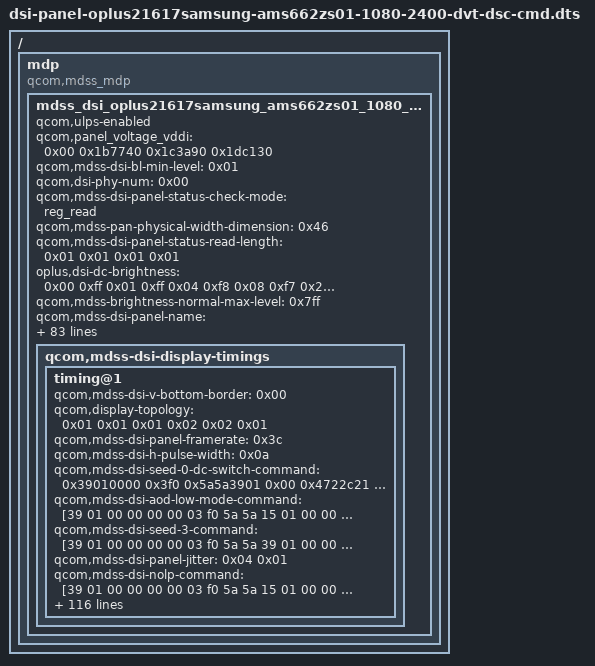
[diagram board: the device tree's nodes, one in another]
/dts-v1/;

/ {
	mdp {
		compatible = "qcom,mdss_mdp";
		mdss_dsi_oplus21617samsung_ams662zs01_1080_2400_cmd_dvt: qcom,mdss_dsi_oplus21617samsung_ams662zs01_1080_2400_cmd_dvt {
			qcom,ulps-enabled;
			qcom,panel_voltage_vddi = <0x00 0x1b7740 0x1c3a90 0x1dc130>;
			qcom,mdss-dsi-bl-min-level = <0x01>;
			qcom,dsi-phy-num = <0x00>;
			qcom,mdss-dsi-panel-status-check-mode = "reg_read";
			qcom,mdss-pan-physical-width-dimension = <0x46>;
			qcom,mdss-dsi-panel-status-read-length = <0x01 0x01 0x01 0x01>;
			oplus,dsi-dc-brightness = <0x00 0xff 0x01 0xff 0x04 0xf8 0x08 0xf7 0x23 0xf5 0x69 0xf3 0xc3 0xf0 0xeb 0xee 0x131 0xe9 0x190 0xe1 0x1f4 0xd7 0x244 0xcd 0x24f 0xc3 0x294 0xaf 0x2d0 0x9b 0x30c 0x87 0x339 0x73 0x361 0x5f 0x384 0x4c 0x3c3 0x37 0x3e8 0x26 0x41a 0x12 0x44c 0x00>;
			qcom,mdss-brightness-normal-max-level = <0x7ff>;
			qcom,mdss-dsi-panel-name = "samsung ams662zs01 dvt dsc cmd mode panel";
			oplus,mdss-dsi-osc-clk-mode1-rate = <0x2c81c>;
			qcom,mdss-pan-physical-height-dimension = <0x99>;
			oplus,dc-apollo-backlight-sync-level = <0x44c>;
			qcom,mdss-dsi-te-using-te-pin;
			oplus,dc_apollo_sync_enable;
			qcom,esd-check-enabled;
			qcom,mdss-dsi-dc-backlight-level = <0x44c>;
			qcom,mdss-dsi-te-dcs-command = <0x01>;
			qcom,mdss-dsi-color-order = "rgb_swap_rgb";
			qcom,dsi-select-clocks = "mux_byte_clk0\0mux_pixel_clk0\0src_byte_clk0\0src_pixel_clk0\0shadow_byte_clk0\0shadow_pixel_clk0";
			qcom,mdss-dsi-panel-status-value = <0x9f 0x00 0x01 0x80>;
			qcom,mdss-dsi-underflow-color = <0xff>;
			qcom,platform-panel-vddr-aod-en-gpio = <0x93 0xa3 0x00>;
			qcom,mdss-dsi-lane-2-state;
			qcom,mdss-dsi-te-check-enable;
			qcom,mdss-dsi-bllp-eof-power-mode;
			oplus,mdss-dsi-osc-clk-mode0-rate = <0x2c04c>;
			oplus,dc-apollo-backlight-sync-level-pcc-min = <0x5460>;
			oplus,esd-err-trigger-polarity = <0x01>;
			oplus,apollo-sync-brightness-level = <0x2c7>;
			qcom,mdss-dsi-mdp-trigger = "none";
			qcom,dsi-ctrl-num = <0x00>;
			qcom,mdss-dsi-bl-max-level = <0xfff>;
			qcom,mdss-dsi-panel-blackness-level = <0x7d0>;
			oplus,dc-apollo-backlight-sync-level-pcc-max = <0x7ff8>;
			qcom,platform-reset-gpio = <0x93 0x18 0x00>;
			qcom,mdss-dsi-panel-peak-brightness = <0x5265c0>;
			qcom,mdss-dsi-lane-3-state;
			qcom,panel_voltage_vddr = <0x01 0x1b7740 0x1c3a90 0x1dc130>;
			qcom,mdss-dsi-panel-hdr-color-primaries = <0x3d13 0x4042 0x84d0 0x3e80 0x33c2 0x86c4 0x1d4c 0xbb8>;
			qcom,mdss-dsi-virtual-channel-id = <0x00>;
			oplus,apollo_backlight_enable;
			qcom,dsi-dyn-clk-enable;
			qcom,mdss-dsi-reset-sequence = <0x00 0x00 0x00 0x01 0x01 0x06>;
			qcom,dynamic-mode-switch-type = "dynamic-resolution-switch-immediate";
			oplus,esd-err-flag-gpio = <0x93 0x54 0x00>;
			qcom,mdss-dsi-panel-type = "dsi_cmd_mode";
			qcom,dynamic-mode-switch-enabled;
			qcom,dsi-dyn-clk-list = <0x2faf0800 0x3178cb80>;
			qcom,mdss-dsi-lane-0-state;
			qcom,panel_voltage_vddr_name = "vddio";
			qcom,mdss-dsi-dma-trigger = "trigger_sw";
			qcom,mdss-dsi-panel-hdr-enabled;
			qcom,mdss-dsi-panel-status-command-state = "dsi_hs_mode";
			qcom,mdss-dsi-te-pin-select = <0x01>;
			qcom,mdss-dsi-bl-normal-max-level = <0x7ff>;
			oplus,mdss-dsi-manufacture = "samsung1024";
			phandle = <0x5c5>;
			qcom,mdss-dsi-bllp-power-mode;
			qcom,panel-supply-entries = <0x61e>;
			qcom,mdss-dsi-stream = <0x00>;
			oplus,dsi-fod-brightness = <0x00 0xff 0x04 0xee 0x100 0xe5 0x10a 0xe4 0x154 0xdc 0x1ae 0xd2 0x1fa 0xca 0x244 0xc2 0x2c6 0xb8 0x2ee 0xb0 0x316 0xab 0x354 0xa5 0x37e 0xa0 0x3d6 0x98 0x41c 0x92 0x460 0x8b 0x49a 0x85 0x4c8 0x80 0x50c 0x79 0x540 0x74 0x570 0x6f 0x596 0x6a 0x5dc 0x63 0x612 0x5e 0x636 0x59 0x670 0x53 0x68a 0x50 0x6c4 0x4a 0x6f2 0x45 0x724 0x40 0x740 0x3d 0x758 0x3a 0x766 0x38 0x7a4 0x32 0x7d6 0x2c 0x7ff 0x28>;
			qcom,mdss-dsi-lp11-init;
			qcom,mdss-dsi-wr-mem-continue = <0x3c>;
			qcom,mdss-dsi-bl-pmic-control-type = "bl_ctrl_dcs";
			qcom,mdss-dsi-lane-map = "lane_map_0123";
			qcom,mdss-dsi-traffic-mode = "non_burst_sync_event";
			qcom,mdss-dsi-border-color = <0x00>;
			qcom,panel_voltage_vddi_name = "vddio";
			qcom,mdss-dsi-panel-controller = <0x519>;
			qcom,mdss-brightness-default-level = <0x190>;
			oplus,mdss-dsi-vendor-name = "AMS662ZS01";
			qcom,mdss-dsi-panel-status-command = <0x6010001 0x500020a 0x60100 0x1050002 0x5000601 0x10500 0x2030006 0x1000105 0x20e00>;
			qcom,mdss-dsi-lane-1-state;
			qcom,mdss-dsi-wr-mem-start = <0x2c>;
			qcom,platform-te-gpio = <0x93 0x52 0x00>;
			oplus,osc-support;
			qcom,mdss-dsi-bpp = <0x18>;
			qcom,mdss-brightness-max-level = <0xfff>;
			qcom,mdss-dsi-display-timings {
                                timing@1 {
					qcom,mdss-dsi-v-bottom-border = <0x00>;
					qcom,display-topology = <0x01 0x01 0x01 0x02 0x02 0x01>;
					qcom,mdss-dsi-panel-framerate = <0x3c>;
					qcom,mdss-dsi-h-pulse-width = <0x0a>;
					qcom,mdss-dsi-seed-0-dc-switch-command = <0x39010000 0x3f0 0x5a5a3901 0x00 0x4722c21 0x390100 0x02 0xf8003901 0x00 0x3f05a5a 0x39010000 0x25d 0x46390100 0x02 0x62003901 0x00 0x3b01662 0x39010000 0x1662 0xff000000 0xff000000 0xff00ffff 0xff00ffff 0xff00ffff 0xff390100 0x03 0xf0a5a539 0x1000014 0x4722c 0x1003901 0x00 0x3f0a5a5>;
					qcom,mdss-dsi-aod-low-mode-command = [39 01 00 00 00 00 03 f0 5a 5a 15 01 00 00 00 00 02 91 01 15 01 00 00 00 00 02 53 25 15 01 00 00 00 00 02 bb 1d 39 01 00 00 00 00 03 f0 a5 a5];
					qcom,mdss-dsi-seed-3-command = [39 01 00 00 00 00 03 f0 5a 5a 39 01 00 00 00 00 03 b0 03 8f 39 01 00 00 00 00 02 8f 25 39 01 00 00 00 00 03 b0 28 f2 39 01 00 00 00 00 02 f2 ce 39 01 00 00 00 00 04 b0 01 18 68 39 01 00 00 00 00 0f 68 e2 1a 1a 1a 82 04 f0 80 00 00 00 00 ff 00 39 01 00 00 00 00 04 b0 00 28 f2 39 01 00 00 00 00 02 f2 c6 39 01 00 00 00 00 03 f0 a5 a5 39 01 00 00 00 00 03 f0 5a 5a 39 01 00 00 00 00 04 72 2c 21 00 39 01 00 00 00 00 02 f8 00 39 01 00 00 00 00 02 5d 06 39 01 00 00 00 00 02 62 00 39 01 00 00 00 00 03 b0 01 62 39 01 00 00 00 00 16 62 d3 01 00 19 fd 00 0b 04 e2 21 e5 e4 de 06 ec fa fd 01 ff ff ff 39 01 00 00 18 00 04 72 2c 01 00 39 01 00 00 00 00 03 f0 a5 a5];
					qcom,mdss-dsi-panel-jitter = <0x04 0x01>;
					qcom,mdss-dsi-nolp-command = [39 01 00 00 00 00 03 f0 5a 5a 15 01 00 00 00 00 02 91 02 15 01 00 00 00 00 02 53 20 39 01 00 00 00 00 03 f0 a5 a5];
					qcom,mdss-dsi-lp1-command = [39 01 00 00 00 00 03 f0 5a 5a 15 01 00 00 00 00 02 91 01 15 01 00 00 00 00 02 53 24 15 01 00 00 00 00 02 bb 1d 39 01 00 00 00 00 03 f0 a5 a5];
					qcom,compression-mode = "dsc";
					qcom,mdss-dsi-hbm-enter-switch-command = <0x39010000 0x3f0 0x5a5a3901 0x1400 0x35107ff 0x39010000 0x391 0x2003901 0x00 0x3b00290 0x39010000 0x290 0x1c390100 0x02 0x53e03901 0x00 0x3f0a5a5>;
					qcom,mdss-dsi-seed-0-switch-command-state = "dsi_hs_mode";
					qcom,mdss-dsi-hbm-on-command-state = "dsi_hs_mode";
					qcom,mdss-dsi-seed-off-command-state = "dsi_hs_mode";
					qcom,mdss-dsi-osc-clk-mode1-command-state = "dsi_hs_mode";
					qcom,mdss-dsi-hbm-off-command-state = "dsi_hs_mode";
					qcom,mdss-dsi-timing-switch-command-state = "dsi_hs_mode";
					qcom,mdss-dsi-seed-2-dc-command = [39 01 00 00 00 00 03 f0 5a 5a 39 01 00 00 00 00 02 5d 86 39 01 00 00 00 00 02 62 00 39 01 00 00 00 00 03 b0 2b 62 39 01 00 00 00 00 16 62 ff 00 00 1d d4 03 12 07 ef 16 fa e2 f7 00 e4 e9 e6 03 ff ff ff 39 01 00 00 00 00 03 f0 a5 a5];
					qcom,mdss-dsi-fps-switch-command-state = "dsi_hs_mode";
					qcom,mdss-dsi-hbm-exit-switch-command = <0x39010000 0x3f0 0x5a5a1501 0x00 0x2532039 0x1000014 0x35107 0xff390100 0x03 0x91020139 0x1000000 0x3b002 0x90390100 0x02 0x90183901 0x00 0x3f0a5a5>;
					oplus,fod-on-vblank = <0x00>;
					qcom,mdss-dsi-seed-1-dc-switch-command-state = "dsi_hs_mode";
					qcom,mdss-dsi-panel-height = <0x960>;
					qcom,mdss-dsc-bit-per-pixel = <0x08>;
					qcom,mdss-dsi-seed-1-dc-command-state = "dsi_hs_mode";
					qcom,mdss-dsc-block-prediction-enable;
					qcom,mdss-dsi-seed-0-command = [39 01 00 00 00 00 03 f0 5a 5a 39 01 00 00 00 00 03 b0 03 8f 39 01 00 00 00 00 02 8f 05 39 01 00 00 00 00 03 b0 28 f2 39 01 00 00 00 00 02 f2 ce 39 01 00 00 00 00 04 b0 01 18 68 39 01 00 00 00 00 0f 68 e2 1a 1a 1a 82 04 f0 80 00 00 00 00 ff 90 39 01 00 00 00 00 04 b0 00 28 f2 39 01 00 00 00 00 02 f2 c6 39 01 00 00 00 00 03 f0 a5 a5 39 01 00 00 00 00 03 f0 5a 5a 39 01 00 00 00 00 04 72 2c 21 00 39 01 00 00 00 00 02 f8 00 39 01 00 00 00 00 02 5d 06 39 01 00 00 00 00 02 62 00 39 01 00 00 00 00 03 b0 01 62 39 01 00 00 00 00 16 62 e5 02 00 1e f2 04 0b 06 e5 28 f3 f7 f8 08 ff ea f4 02 ff ff ff 39 01 00 00 18 00 04 72 2c 01 00 39 01 00 00 00 00 03 f0 a5 a5];
					qcom,mdss-dsi-on-command = [39 01 00 00 00 00 81 9e 11 00 00 89 30 80 09 60 04 38 00 1e 02 1c 02 1c 02 00 02 0e 00 20 02 e3 00 07 00 0c 03 50 03 64 18 00 10 f0 03 0c 20 00 06 0b 0b 33 0e 1c 2a 38 46 54 62 69 70 77 79 7b 7d 7e 01 02 01 00 09 40 09 be 19 fc 19 fa 19 f8 1a 38 1a 78 1a b6 2a f6 2b 34 2b 74 3b 74 6b f4 00 00 00 00 00 00 00 00 00 00 00 00 00 00 00 00 00 00 00 00 00 00 00 00 00 00 00 00 00 00 00 00 00 00 00 00 00 00 00 00 39 01 00 00 00 00 02 c2 14 39 01 00 00 00 00 02 9d 01 05 01 00 00 79 00 01 11 39 01 00 00 00 00 02 35 00 39 01 00 00 00 00 05 2a 00 00 04 37 39 01 00 00 00 00 05 2b 00 00 09 5f 39 01 00 00 00 00 03 f0 5a 5a 39 01 00 00 00 00 03 b0 27 f2 39 01 00 00 00 00 02 f2 00 39 01 00 00 00 00 03 f0 a5 a5 39 01 00 00 00 00 03 f0 5a 5a 39 01 00 00 00 00 03 60 00 00 39 01 00 00 00 00 02 f7 0f 39 01 00 00 00 00 03 f0 a5 a5 39 01 00 00 00 00 02 53 20];
					qcom,mdss-dsi-h-front-porch = <0x21c>;
					qcom,mdss-dsi-aod-hbm-off-command = [39 01 00 00 00 00 03 f0 5a 5a 15 01 00 00 00 00 02 91 02 15 01 00 00 00 00 02 53 20 39 01 00 00 00 00 03 f0 a5 a5 39 01 00 00 00 00 03 f0 5a 5a 15 01 00 00 00 00 02 53 20 39 01 00 00 0a 00 03 51 07 ff 39 01 00 00 00 00 03 91 02 01 39 01 00 00 00 00 03 b0 02 90 39 01 00 00 00 00 02 90 18 39 01 00 00 00 00 03 f0 a5 a5];
					qcom,mdss-dsi-seed-1-dc-switch-command = <0x39010000 0x3f0 0x5a5a3901 0x00 0x4722c21 0x390100 0x02 0xf8003901 0x00 0x3f05a5a 0x39010000 0x25d 0x6390100 0x02 0x62003901 0x00 0x3b00162 0x39010000 0x1662 0xba0c0745 0xd7170c05 0xad48f2dc 0xc407c8e9 0xe91dffff 0xff390100 0x03 0xf0a5a539 0x1000014 0x4722c 0x1003901 0x00 0x3f0a5a5>;
					qcom,mdss-dsc-slice-width = <0x21c>;
					qcom,mdss-dsi-seed-2-command-state = "dsi_hs_mode";
					qcom,mdss-dsi-h-back-porch = <0x28>;
					oplus,fod-off-vblank = <0x01>;
					qcom,mdss-dsi-seed-0-dc-command = [39 01 00 00 00 00 03 f0 5a 5a 39 01 00 00 00 00 02 5d 46 39 01 00 00 00 00 02 62 00 39 01 00 00 00 00 03 b0 16 62 39 01 00 00 00 00 16 62 ff 00 00 00 ff 00 00 00 ff 00 ff ff ff 00 ff ff ff 00 ff ff ff 39 01 00 00 00 00 03 f0 a5 a5];
					qcom,mdss-dsi-timing-switch-command = [39 01 00 00 00 00 03 f0 5a 5a 39 01 00 00 00 00 03 60 00 00 39 01 00 00 00 00 02 f7 0f 39 01 00 00 11 00 03 f0 a5 a5];
					qcom,mdss-dsi-h-left-border = <0x00>;
					qcom,mdss-dsi-seed-2-command = [39 01 00 00 00 00 03 f0 5a 5a 39 01 00 00 00 00 03 b0 03 8f 39 01 00 00 00 00 02 8f 05 39 01 00 00 00 00 03 b0 28 f2 39 01 00 00 00 00 02 f2 ce 39 01 00 00 00 00 04 b0 01 18 68 39 01 00 00 00 00 0f 68 e2 1a 1a 1a 82 04 f0 80 00 00 00 00 ff 00 39 01 00 00 00 00 04 b0 00 28 f2 39 01 00 00 00 00 02 f2 c6 39 01 00 00 00 00 03 f0 a5 a5 39 01 00 00 00 00 03 f0 5a 5a 39 01 00 00 00 00 04 72 2c 21 00 39 01 00 00 00 00 02 f8 00 39 01 00 00 00 00 02 5d 06 39 01 00 00 00 00 02 62 00 39 01 00 00 00 00 03 b0 01 62 39 01 00 00 00 00 16 62 ff 00 00 00 ff 00 00 00 ff 00 ff ff ff 00 ff ff ff 00 ff ff ff 39 01 00 00 18 00 04 72 2c 01 00 39 01 00 00 00 00 03 f0 a5 a5];
					qcom,mdss-dsi-h-right-border = <0x00>;
					qcom,mdss-dsi-osc-clk-mode1-command = [39 01 00 00 00 00 03 f0 5a 5a 39 01 00 00 00 00 03 fc 5a 5a 39 01 00 00 00 00 03 b0 2a c5 39 01 00 00 00 00 05 c5 0d 10 80 45 39 01 00 00 00 00 03 b0 2e c5 39 01 00 00 00 00 03 c5 70 74 39 01 00 00 00 00 03 f0 a5 a5 39 01 00 00 00 00 03 fc a5 a5];
					qcom,mdss-dsc-slice-height = <0x1e>;
					qcom,mdss-dsi-seed-0-command-state = "dsi_hs_mode";
					qcom,mdss-dsi-h-sync-skew = <0x00>;
					qcom,mdss-dsi-panel-width = <0x438>;
					qcom,mdss-dsi-v-pulse-width = <0x02>;
					qcom,mdss-dsi-aod-hbm-on-command = <0x39010000 0x3f0 0x5a5a1501 0x00 0x2910239 0x1000000 0x25320 0x39010000 0x3f0 0xa5a53901 0x00 0x3f05a5a 0x39010000 0x14000351 0x7ff3901 0x00 0x3910200 0x39010000 0x3b0 0x2903901 0x00 0x2901c39 0x1000000 0x253e0 0x39010000 0x351 0xfff3901 0x00 0x3f0a5a5>;
					qcom,mdss-dsi-on-command-state = "dsi_lp_mode";
					qcom,mdss-dsi-panel-phy-timings = [00 1d 07 07 17 22 07 07 08 02 04 00 19 0c];
					qcom,mdss-dsi-hbm-on-command = [39 01 00 00 00 00 03 f0 5a 5a 39 01 00 00 0a 00 03 51 07 ff 39 01 00 00 00 00 03 91 02 00 39 01 00 00 00 00 03 b0 02 90 39 01 00 00 00 00 02 90 1c 39 01 00 00 00 00 02 53 e0 39 01 00 00 00 00 03 51 0f ff 39 01 00 00 00 00 03 f0 a5 a5];
					qcom,mdss-dsi-v-back-porch = <0x09>;
					qcom,mdss-dsi-seed-2-switch-command-state = "dsi_hs_mode";
					qcom,default-topology-index = <0x00>;
					qcom,mdss-dsi-post-on-backlight = <0x5010000 0x129>;
					qcom,mdss-dsi-v-top-border = <0x00>;
					qcom,mdss-dsi-fps-switch-command = <0x39010000 0x3f0 0x5a5a3901 0x00 0x3b028f2 0x39010000 0x2f2 0xce390100 0x04 0xb001b465 0x39010000 0x2165 0x9700928 0x9030898 0x82c07bf 0x6ea0612 0x53a0462 0x38b02b2 0x16d0028 0x280028 0x39010000 0x4b0 0x28f239 0x1000000 0x2f2c6 0x39010000 0x360 0x3901 0x00 0x3b008f2 0x39010000 0x2f2 0x4390100 0x02 0xf70f3901 0x1100 0x3f0a5a5>;
					qcom,mdss-dsi-seed-2-dc-switch-command = <0x39010000 0x3f0 0x5a5a3901 0x00 0x4722c21 0x390100 0x02 0xf8003901 0x00 0x3f05a5a 0x39010000 0x25d 0x86390100 0x02 0x62003901 0x00 0x3b02b62 0x39010000 0x1662 0xff00001d 0xd4031207 0xef16fae2 0xf700e4e9 0xe603ffff 0xff390100 0x03 0xf0a5a539 0x1000014 0x4722c 0x1003901 0x00 0x3f0a5a5>;
					qcom,mdss-dsi-hbm-off-command = <0x39010000 0x3f0 0x5a5a1501 0x00 0x2532039 0x1000014 0x35107 0xff390100 0x03 0x91020139 0x1000000 0x3b002 0x90390100 0x02 0x90183901 0x00 0x3f0a5a5>;
					qcom,mdss-dsi-osc-clk-mode0-command-state = "dsi_hs_mode";
					qcom,mdss-dsc-slice-per-pkt = <0x02>;
					qcom,mdss-dsi-seed-2-dc-switch-command-state = "dsi_hs_mode";
					qcom,mdss-dsi-aod-high-mode-command = [39 01 00 00 00 00 03 f0 5a 5a 15 01 00 00 00 00 02 91 01 15 01 00 00 00 00 02 53 24 15 01 00 00 00 00 02 bb 1d 39 01 00 00 00 00 03 f0 a5 a5];
					qcom,mdss-dsi-normal-hbm-on-command = [39 01 00 00 00 00 03 f0 5a 5a 39 01 00 00 14 00 03 51 07 ff 39 01 00 00 00 00 03 91 02 00 39 01 00 00 00 00 03 b0 02 90 39 01 00 00 00 00 02 90 1c 39 01 00 00 00 00 02 53 e0 39 01 00 00 00 00 03 51 0f ff 39 01 00 00 00 00 03 f0 a5 a5];
					qcom,mdss-dsi-h-sync-pulse = <0x00>;
					qcom,mdss-dsi-off-command = [39 01 00 00 00 00 03 f0 5a 5a 15 01 00 00 00 00 02 91 02 15 01 00 00 00 00 02 53 20 39 01 00 00 00 00 03 f0 a5 a5 05 01 00 00 0b 00 01 28 05 01 00 00 79 00 01 10];
					qcom,mdss-dsi-seed-1-dc-command = [39 01 00 00 00 00 03 f0 5a 5a 39 01 00 00 00 00 02 5d 06 39 01 00 00 00 00 02 62 00 39 01 00 00 00 00 03 b0 01 62 39 01 00 00 00 00 16 62 ba 0c 07 45 d7 17 0c 05 ad 48 f2 dc c4 07 c8 e9 e9 1d ff ff ff 39 01 00 00 00 00 03 f0 a5 a5];
					qcom,mdss-dsi-seed-3-command-state = "dsi_hs_mode";
					qcom,mdss-dsi-seed-off-command = [39 01 00 00 00 00 03 f0 5a 5a 15 01 00 00 00 00 02 5d 00 15 01 00 00 00 00 02 62 01 39 01 00 00 00 00 03 f0 a5 a5];
					qcom,mdss-dsi-seed-2-dc-command-state = "dsi_hs_mode";
					qcom,mdss-dsi-seed-0-dc-switch-command-state = "dsi_hs_mode";
					qcom,mdss-dsi-seed-0-dc-command-state = "dsi_hs_mode";
					qcom,mdss-dsc-bit-per-component = <0x08>;
					qcom,mdss-dsi-seed-1-switch-command-state = "dsi_hs_mode";
					qcom,mdss-dsi-v-front-porch = <0x15>;
					qcom,mdss-dsi-seed-1-command = [39 01 00 00 00 00 03 f0 5a 5a 39 01 00 00 00 00 03 b0 03 8f 39 01 00 00 00 00 02 8f 25 39 01 00 00 00 00 03 b0 28 f2 39 01 00 00 00 00 02 f2 ce 39 01 00 00 00 00 04 b0 01 18 68 39 01 00 00 00 00 0f 68 e2 1a 1a 1a 82 04 f0 80 00 00 00 00 ff 00 39 01 00 00 00 00 04 b0 00 28 f2 39 01 00 00 00 00 02 f2 c6 39 01 00 00 00 00 03 f0 a5 a5 39 01 00 00 00 00 03 f0 5a 5a 39 01 00 00 00 00 04 72 2c 21 00 39 01 00 00 00 00 02 f8 00 39 01 00 00 00 00 02 5d 06 39 01 00 00 00 00 02 62 00 39 01 00 00 00 00 03 b0 01 62 39 01 00 00 00 00 16 62 d3 01 00 19 fd 00 0b 04 e2 21 e5 e4 de 06 ec fa fd 01 ff ff ff 39 01 00 00 18 00 04 72 2c 01 00 39 01 00 00 00 00 03 f0 a5 a5];
					qcom,mdss-dsi-osc-clk-mode0-command = [39 01 00 00 00 00 03 f0 5a 5a 39 01 00 00 00 00 03 fc 5a 5a 39 01 00 00 00 00 03 b0 2a c5 39 01 00 00 00 00 05 c5 0d 10 80 45 39 01 00 00 00 00 03 b0 2e c5 39 01 00 00 00 00 03 c5 6f 39 39 01 00 00 00 00 03 f0 a5 a5 39 01 00 00 00 00 03 fc a5 a5];
					qcom,mdss-dsi-off-command-state = "dsi_hs_mode";
					qcom,mdss-dsi-seed-1-command-state = "dsi_hs_mode";
                                };
                        };
		};
	};
};

